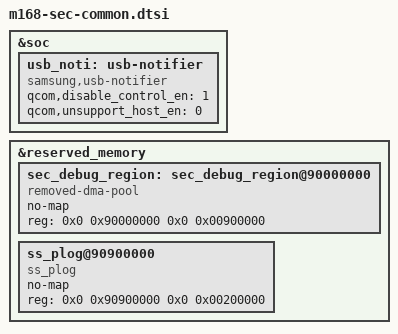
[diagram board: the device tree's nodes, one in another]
/* Copyright (c) 2019, The Linux Foundation. All rights reserved.
 *
 * This program is free software; you can redistribute it and/or modify
 * it under the terms of the GNU General Public License version 2 and
 * only version 2 as published by the Free Software Foundation.
 *
 * This program is distributed in the hope that it will be useful,
 * but WITHOUT ANY WARRANTY; without even the implied warranty of
 * MERCHANTABILITY or FITNESS FOR A PARTICULAR PURPOSE.  See the
 * GNU General Public License for more details.
 */

&soc {
	usb_noti: usb-notifier {
		compatible = "samsung,usb-notifier";
		qcom,disable_control_en = <1>;
		qcom,unsupport_host_en = <0>;
	};
};

&reserved_memory {
	/* CONFIG_SEC_DEBUG reserves 9MB */
	sec_debug_region: sec_debug_region@90000000 {
		compatible = "removed-dma-pool";
		no-map;
		reg = <0x0 0x90000000 0x0 0x00900000>;
	};

	ss_plog@90900000 {
		compatible = "ss_plog";
		no-map;
		reg = <0x0 0x90900000 0x0 0x00200000>;
	};
};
